# STMP3770 register map
Vendor: Freescale Semiconductor (NXP); Series: STMP37xx; File version: 1.0
CPU: other r0p0, little endian, no MPU, no FPU, 2 interrupt priority bits
Registers are 32-bit, read-write, reset 0x0 unless marked. A register's access mark holds for its fields unless they carry their own. Offsets are from the block's base; [hi:lo] are bit positions; {n}, {i} and the like mark numbered series.

## LCDIF — STMP3770 LCDIF (eLCDIF) 显示控制器，支持 MPU/8080 并行接口、VSYNC 模式与 DOTCLK 模式，集成 DMA 帧缓冲、RGB-to-YCbCr 4:2:2 CSC 转换、DVI 输出及引脚共享仲裁。基地址 0x80030000。
Base 0x80030000
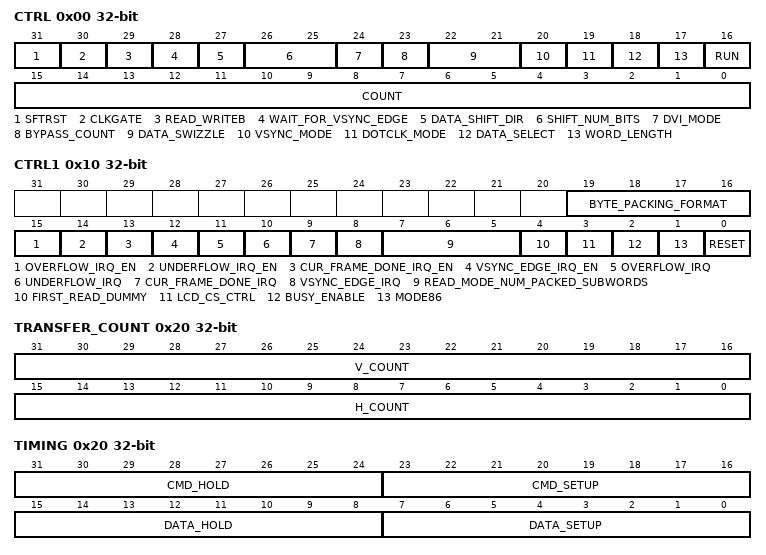
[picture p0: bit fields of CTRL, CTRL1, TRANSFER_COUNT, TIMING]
0x00 CTRL — LCDIF 通用控制寄存器，控制数据传输启动、数据格式、接口模式、字节序、移位及复位等全局行为。
  [31] SFTRST — 软复位，写 1 对 LCDIF 模块进行软件复位。
  [30] CLKGATE — 时钟门控，1 时关闭 LCDIF 内部时钟以节省功耗。
  [29] READ_WRITEB — 读写方向控制，0=写（发送），1=读（接收）。
  [28] WAIT_FOR_VSYNC_EDGE — 等待 VSYNC 边沿后再启动帧传输，用于帧同步对齐。
  [27] DATA_SHIFT_DIR — 数据移位方向，0=左移，1=右移。
    0=TXDATA_SHIFT_LEFT; 1=TXDATA_SHIFT_RIGHT
  [26:25] SHIFT_NUM_BITS — 数据移位的位数（0-3），指定像素数据在输出前左/右移的位数。
  [24] DVI_MODE — DVI 输出模式使能，1 时启用 DVI/数字视频接口输出。
  [23] BYPASS_COUNT — 旁路内部行列计数器，1 时由外部逻辑或 DMA 直接控制传输终止。
  [22:21] DATA_SWIZZLE — 输入数据字节序调整（Swizzle），控制 32 位字内各字节的排列顺序。
  [20] VSYNC_MODE — VSYNC 接口模式使能，1 表示使用 VSYNC 同步模式。
  [19] DOTCLK_MODE — DOTCLK 接口模式使能，1 表示使用同步 DOTCLK 时序驱动 RGB 屏。
  [18] DATA_SELECT — MPU/8080 接口命令/数据选择，0=命令模式，1=数据模式。
    0=CMD_MODE; 1=DATA_MODE
  [17] WORD_LENGTH — 像素字长选择，0=16 位，1=24 位。
    0=NO_SWAP; 1=BIG_ENDIAN_SWAP
  [16] RUN — 启动 LCDIF 数据传输，写 1 使能传输引擎运行。
    0=_16_BIT; 1=_8_BIT
  [15:0] COUNT — LCD 数据格式选择，编码像素数据输出位宽（0=16 位，1=8 位，2=18 位，3=24 位）。
    0=_16_BIT; 1=_8_BIT; 2=_18_BIT; 3=_24_BIT
0x10 CTRL1 — LCDIF 通用控制寄存器 1，包含 LCD 复位、接口子模式、中断状态/使能及字节打包格式。
  [19:16] BYTE_PACKING_FORMAT — 字节打包格式，32 位字内各字节通道的有效/无效掩码，用于非 32 位对齐像素格式。
  [15] OVERFLOW_IRQ_EN — 溢出中断使能，1 时允许 OVERFLOW_IRQ 产生中断。
  [14] UNDERFLOW_IRQ_EN — 下溢中断使能，1 时允许 UNDERFLOW_IRQ 产生中断。
  [13] CUR_FRAME_DONE_IRQ_EN — 当前帧完成中断使能，1 时允许 CUR_FRAME_DONE_IRQ 产生中断。
  [12] VSYNC_EDGE_IRQ_EN — VSYNC 边沿中断使能，1 时允许 VSYNC_EDGE_IRQ 产生中断。
  [11] OVERFLOW_IRQ — 溢出中断状态，1 表示 RXFIFO/TXFIFO 溢出中断请求。
    0=NO_REQUEST; 1=REQUEST
  [10] UNDERFLOW_IRQ — 下溢中断状态，1 表示 TXFIFO 下溢中断请求。
    0=NO_REQUEST; 1=REQUEST
  [9] CUR_FRAME_DONE_IRQ — 当前帧完成中断状态，1 表示当前帧传输完成中断请求。
    0=NO_REQUEST; 1=REQUEST
  [8] VSYNC_EDGE_IRQ — VSYNC 边沿中断状态，1 表示检测到 VSYNC 边沿中断请求。
    0=NO_REQUEST; 1=REQUEST
  [7:5] READ_MODE_NUM_PACKED_SUBWORDS — 读模式下每字内打包的子字数量，决定一次 32 位读操作中包含的有效像素子字数。
  [4] FIRST_READ_DUMMY — 首次读虚拟周期请求，1 时在读序列开头插入一个虚拟读周期。
    0=NO_REQUEST; 1=REQUEST
  [3] LCD_CS_CTRL — LCD 片选信号控制，直接控制 CS 引脚输出电平。
  [2] BUSY_ENABLE — BUSY 信号检测使能，1 时 LCDIF 在 MPU 读/写期间检测外部 BUSY 信号。
    0=BUSY_DISABLED; 1=BUSY_ENABLED
  [1] MODE86 — MPU 接口子模式选择，0=8080 模式，1=6800 模式。
    0=_8080_MODE; 1=_6800_MODE
  [0] RESET — LCD 面板硬件复位信号控制，0=低电平复位，1=高电平释放。
    0=LCDRESET_LOW; 1=LCDRESET_HIGH
0x20 TRANSFER_COUNT (alternate view of TIMING) — LCDIF 有效数据传输计数寄存器，定义一帧内水平与垂直方向的像素数量。
  [31:16] V_COUNT — 垂直方向有效像素计数（行数）。
  [15:0] H_COUNT — 水平方向有效像素计数（每行像素数）。
0x20 TIMING — LCD 接口时序寄存器，配置 MPU/8080 并行接口的命令与数据建立/保持周期。注：该物理地址在 System 模式下为 TRANSFER_COUNT。
  [31:24] CMD_HOLD — 命令写操作的保持周期数（WR 无效后 CMD 保持有效的时钟数）。
  [23:16] CMD_SETUP — 命令写操作的建立周期数（CMD 有效到 WR 有效之间的等待时钟数）。
  [15:8] DATA_HOLD — 数据写操作的保持周期数（WR 无效后 DATA 保持有效的时钟数）。
  [7:0] DATA_SETUP — 数据写操作的建立周期数（DATA 有效到 WR 有效之间的等待时钟数）。
0x30 CUR_BUF (alternate view of VDCTRL1) — LCD 接口当前帧缓冲地址寄存器，存储 DMA 当前正在传输的帧数据物理地址。
  [31:0] ADDR — 当前帧缓冲在系统内存中的 32 位物理地址。
0x30 VDCTRL1 — LCDIF VSYNC/DOTCLK 模式控制寄存器 1，定义 VSYNC 周期（帧总周期）。注：该物理地址在 System 模式下为 CUR_BUF。
  [31:0] VSYNC_PERIOD — VSYNC 周期值，表示一帧的总时钟周期数（含有效与消隐区）。
0x40 NEXT_BUF (alternate view of VDCTRL2) — LCD 接口下一帧缓冲地址寄存器，存储 DMA 下一帧待传输的帧数据物理地址。
  [31:0] ADDR — 下一帧缓冲在系统内存中的 32 位物理地址，硬件在当前帧完成后自动切换。
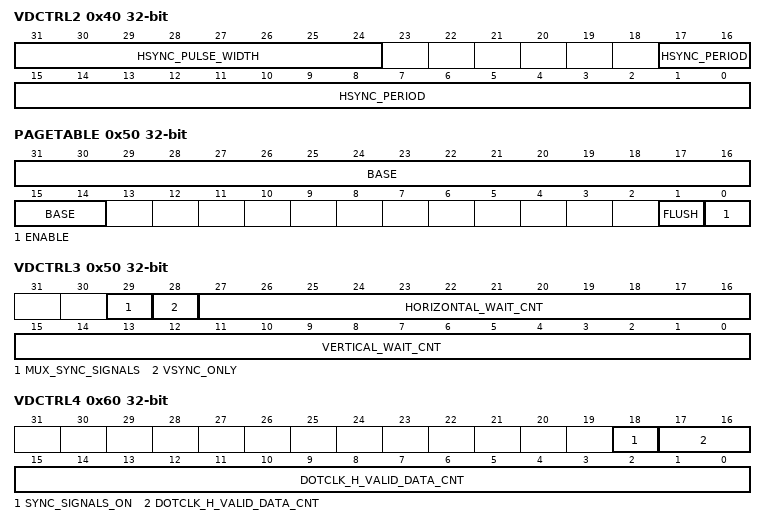
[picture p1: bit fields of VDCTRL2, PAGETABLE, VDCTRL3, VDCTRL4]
0x40 VDCTRL2 — LCDIF VSYNC/DOTCLK 模式控制寄存器 2，定义 HSYNC 周期与脉冲宽度。注：该物理地址在 System 模式下为 NEXT_BUF。
  [31:24] HSYNC_PULSE_WIDTH — HSYNC 脉冲宽度，表示水平同步脉冲持续的有效时钟周期数。
  [17:0] HSYNC_PERIOD — HSYNC 周期值，表示一行的总时钟周期数（含有效与消隐区）。
0x50 PAGETABLE (alternate view of VDCTRL3) — LCDIF 页表寄存器，使能 DMA 页表寻址并配置页表基地址。
  [31:14] BASE — 页表基地址的高 18 位（以 16KB 对齐），指向内存中的页表起始位置。
  [1] FLUSH — 页表刷新，写 1 强制刷新内部页表缓存。
  [0] ENABLE — 页表机制使能，1 时 DMA 通过页表进行分散/聚集式地址转换。
0x50 VDCTRL3 — LCDIF VSYNC/DOTCLK 模式控制寄存器 3，配置行列等待计数及同步信号复用。注：该物理地址在 System 模式下为 PAGETABLE。
  [29] MUX_SYNC_SIGNALS — 同步信号复用使能，1 时将 VSYNC/HSYNC/ENABLE 信号复用输出。
  [28] VSYNC_ONLY — 仅 VSYNC 模式，1 时关闭 DOTCLK 输出，仅使用 VSYNC 同步。
  [27:16] HORIZONTAL_WAIT_CNT — 水平等待计数，表示 HSYNC 有效后到首像素有效数据前的时钟等待周期数。
  [15:0] VERTICAL_WAIT_CNT — 垂直等待计数，表示 VSYNC 有效后到首行有效数据前的行等待周期数。
0x60 VDCTRL4 — LCDIF VSYNC/DOTCLK 模式控制寄存器 4，配置水平有效数据计数及同步信号强制输出。
  [18] SYNC_SIGNALS_ON — 强制同步信号输出使能，1 时持续输出 HSYNC/VSYNC/ENABLE 波形。
  [17:0] DOTCLK_H_VALID_DATA_CNT — DOTCLK 模式下每行有效数据像素计数。
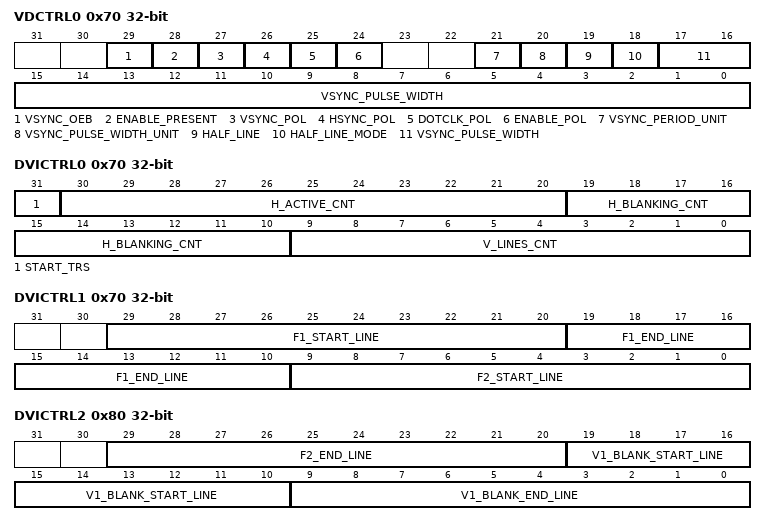
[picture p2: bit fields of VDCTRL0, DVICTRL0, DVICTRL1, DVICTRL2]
0x70 VDCTRL0 — LCDIF VSYNC/DOTCLK 模式控制寄存器 0，配置 VSYNC 脉冲宽度、极性、半行模式及同步信号属性。
  [29] VSYNC_OEB — VSYNC 引脚方向控制，0=输出（内部产生 VSYNC），1=输入（外部接收 VSYNC）。
    0=VSYNC_OUTPUT; 1=VSYNC_INPUT
  [28] ENABLE_PRESENT — 数据使能信号（ENABLE/DE）存在标志，1 表示接口使用 DE 信号。
  [27] VSYNC_POL — VSYNC 垂直同步极性，0=低电平有效，1=高电平有效。
  [26] HSYNC_POL — HSYNC 水平同步极性，0=低电平有效，1=高电平有效。
  [25] DOTCLK_POL — DOTCLK 像素时钟极性，0=上升沿采样，1=下降沿采样。
  [24] ENABLE_POL — 数据使能信号（ENABLE/DE）极性，0=低电平有效，1=高电平有效。
  [21] VSYNC_PERIOD_UNIT — VSYNC 周期单位，0=以像素时钟为单位，1=以行为单位。
  [20] VSYNC_PULSE_WIDTH_UNIT — VSYNC 脉冲宽度单位，0=以像素时钟为单位，1=以行为单位。
  [19] HALF_LINE — 半行指示，当前处于半行扫描状态标志（只读）。
  [18] HALF_LINE_MODE — 半行模式使能，1 时每帧按半行粒度进行扫描时序控制。
  [17:0] VSYNC_PULSE_WIDTH — VSYNC 脉冲宽度，表示垂直同步脉冲持续的有效时钟周期数。
0x70 DVICTRL0 (alternate view of VDCTRL0) — 数字视频接口控制寄存器 0，配置 DVI 输出时视频帧的行数、水平消隐与有效像素。注：该物理地址在 VSYNC/DOTCLK 模式下为 VDCTRL0。
  [31] START_TRS — DVI 传输启动，写 1 开始 DVI 数据流输出。
  [30:20] H_ACTIVE_CNT — 水平有效像素计数（每行中有效像素数）。
  [19:10] H_BLANKING_CNT — 水平消隐期像素计数（每行中无效像素时钟数）。
  [9:0] V_LINES_CNT — 每帧有效视频行数（垂直方向总行数）。
0x70 DVICTRL1 (alternate view of VDCTRL0) — 数字视频接口控制寄存器 1，配置隔行扫描时场 1 与场 2 的起止行位置。注：该物理地址在 VSYNC/DOTCLK 模式下为 VDCTRL0，与 DVICTRL0 共享地址。
  [29:20] F1_START_LINE — 场 1（F1）起始行号，定义隔行扫描第一场的第一有效行。
  [19:10] F1_END_LINE — 场 1（F1）结束行号，定义隔行扫描第一场的最后一有效行。
  [9:0] F2_START_LINE — 场 2（F2）起始行号，定义隔行扫描第二场的第一有效行。
0x80 DVICTRL2 — 数字视频接口控制寄存器 2，配置场 1 垂直消隐及场 2 结束行位置。
  [29:20] F2_END_LINE — 场 2（F2）结束行号，定义隔行扫描第二场的最后一有效行。
  [19:10] V1_BLANK_START_LINE — 场 1 垂直消隐开始行号，定义第一场有效视频结束、消隐开始的行。
  [9:0] V1_BLANK_END_LINE — 场 1 垂直消隐结束行号，定义第一场消隐期结束、有效视频开始的行。
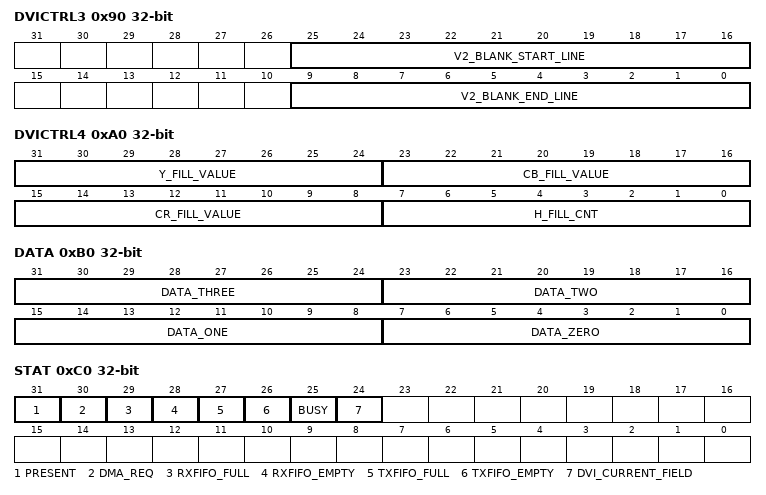
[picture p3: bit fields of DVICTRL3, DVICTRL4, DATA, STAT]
0x90 DVICTRL3 — 数字视频接口控制寄存器 3，配置场 2 垂直消隐起止行位置。
  [25:16] V2_BLANK_START_LINE — 场 2 垂直消隐开始行号，定义第二场有效视频结束、消隐开始的行。
  [9:0] V2_BLANK_END_LINE — 场 2 垂直消隐结束行号，定义第二场消隐期结束、有效视频开始的行。
0xA0 DVICTRL4 — 数字视频接口控制寄存器 4，配置 DVI 水平填充计数及 YCbCr 填充值。
  [31:24] Y_FILL_VALUE — Y 亮度填充值，消隐期输出的 Y 分量默认值。
  [23:16] CB_FILL_VALUE — Cb 色度填充值，消隐期输出的 Cb 分量默认值。
  [15:8] CR_FILL_VALUE — Cr 色度填充值，消隐期输出的 Cr 分量默认值。
  [7:0] H_FILL_CNT — 水平填充像素计数，定义每行消隐期插入的填充像素数。
0xB0 DATA — LCD 接口数据寄存器，用于 PIO 方式直接写入 4 字节像素数据到 TXFIFO。
  [31:24] DATA_THREE — 字节 3 数据，32 位字中最高有效字节对应的像素数据。
  [23:16] DATA_TWO — 字节 2 数据，32 位字中次高字节对应的像素数据。
  [15:8] DATA_ONE — 字节 1 数据，32 位字中次低字节对应的像素数据。
  [7:0] DATA_ZERO — 字节 0 数据，32 位字中最低有效字节对应的像素数据。
0xC0 BM_ERROR_STAT ro (alternate view of STAT) — 总线主设备错误状态寄存器，记录 DMA 传输发生总线错误时的出错地址。注：该物理地址在其他模式下作为 STAT（状态寄存器）使用。
  [31:0] ADDR — DMA 总线错误发生时的 32 位出错内存地址。
0xC0 STAT — LCD 接口状态寄存器，反映当前运行状态、FIFO 状态及 DMA 请求标志。注：该物理地址在 System 模式下为 BM_ERROR_STAT（总线错误状态寄存器）。
  [31] PRESENT — 模块存在标志，1 表示 LCDIF 硬件模块已集成并可用。
  [30] DMA_REQ — DMA 请求标志，1 表示 LCDIF 正在向 DMA 控制器请求数据传输。
  [29] RXFIFO_FULL — 接收 FIFO 满标志，1 表示 RXFIFO 已满。
  [28] RXFIFO_EMPTY — 接收 FIFO 空标志，1 表示 RXFIFO 已空。
  [27] TXFIFO_FULL — 发送 FIFO 满标志，1 表示 TXFIFO 已满。
  [26] TXFIFO_EMPTY — 发送 FIFO 空标志，1 表示 TXFIFO 已空。
  [25] BUSY — 忙标志，1 表示 LCDIF 正在执行数据传输或时序生成。
  [24] DVI_CURRENT_FIELD — DVI 当前场指示，0=场 1，1=场 2（隔行输出时）。
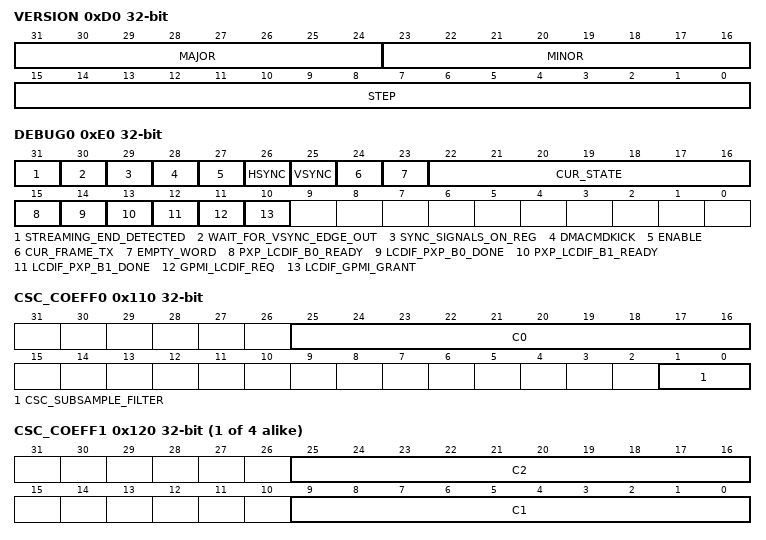
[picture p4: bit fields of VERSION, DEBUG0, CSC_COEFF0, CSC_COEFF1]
0xD0 VERSION ro — LCD 接口版本寄存器，读取硬件版本号（主/次/步进）。
  [31:24] MAJOR — 主版本号（MAJOR），标识当前硬件的主要版本。
  [23:16] MINOR — 次版本号（MINOR），标识当前硬件的次要版本。
  [15:0] STEP — 步进版本号（STEP），标识当前硬件的修订步进。
0xE0 DEBUG0 ro — LCD 接口调试寄存器 0，提供内部状态机、握手信号及同步信号的实时快照。
  [31] STREAMING_END_DETECTED — 流结束检测标志，1 表示 LCDIF 检测到数据流传输结束。
  [30] WAIT_FOR_VSYNC_EDGE_OUT — WAIT_FOR_VSYNC_EDGE 输出的实时状态，反映 CTRL 中该位的内部生效状态。
  [29] SYNC_SIGNALS_ON_REG — 同步信号强制输出寄存器位的实时状态，反映 VDCTRL4.SYNC_SIGNALS_ON 的生效状态。
  [28] DMACMDKICK — DMA 命令触发（Kick）信号，1 表示 DMA 命令已被触发执行。
  [27] ENABLE — 内部 ENABLE/DE 数据使能信号实时状态。
  [26] HSYNC — 内部 HSYNC 信号实时状态。
  [25] VSYNC — 内部 VSYNC 信号实时状态。
  [24] CUR_FRAME_TX — 当前帧传输中标志，1 表示 LCDIF 正在传输当前帧数据。
  [23] EMPTY_WORD — 空字标志，1 表示当前 TXFIFO 输出为空字（填充数据）。
  [22:16] CUR_STATE — 当前状态机状态码，反映 LCDIF 内部控制状态机的当前状态编号。
  [15] PXP_LCDIF_B0_READY — PXP 到 LCDIF 的 Buffer 0 就绪信号，1 表示 PXP 已准备好 Buffer 0 数据供 LCDIF 读取。
  [14] LCDIF_PXP_B0_DONE — LCDIF 到 PXP 的 Buffer 0 完成信号，1 表示 LCDIF 已完成 Buffer 0 的像素处理。
  [13] PXP_LCDIF_B1_READY — PXP 到 LCDIF 的 Buffer 1 就绪信号，1 表示 PXP 已准备好 Buffer 1 数据供 LCDIF 读取。
  [12] LCDIF_PXP_B1_DONE — LCDIF 到 PXP 的 Buffer 1 完成信号，1 表示 LCDIF 已完成 Buffer 1 的像素处理。
  [11] GPMI_LCDIF_REQ — GPMI 向 LCDIF 发出的引脚共享请求信号。
  [10] LCDIF_GPMI_GRANT — GPMI 对 LCDIF 的引脚共享授权信号，1 表示 GPMI 已授权 LCDIF 使用共享引脚。
0x110 CSC_COEFF0 — RGB 到 YCbCr 4:2:2 色彩空间转换系数寄存器 0，配置色度子采样滤波器及 CSC 矩阵系数 C0。
  [25:16] C0 — CSC 转换矩阵系数 C0（10 位有符号定点数），用于 RGB 到 YCbCr 的线性变换。
  [1:0] CSC_SUBSAMPLE_FILTER — 色度子采样滤波器模式选择，0=采样保持，2=间插式，3=共位式。
    0=SAMPLE_AND_HOLD; 1=RSRVD; 2=INTERSTITIAL; 3=COSITED
{0x110+0x10*i} CSC_COEFF{i} (i=1..4) — RGB 到 YCbCr 4:2:2 色彩空间转换系数寄存器 {i}，配置 CSC 矩阵系数 C{2i-1} 与 C{2i}。
  [25:16] C{2i} — CSC 转换矩阵系数 C{2i}（10 位有符号定点数）。
  [9:0] C{2i-1} — CSC 转换矩阵系数 C{2i-1}（10 位有符号定点数）。
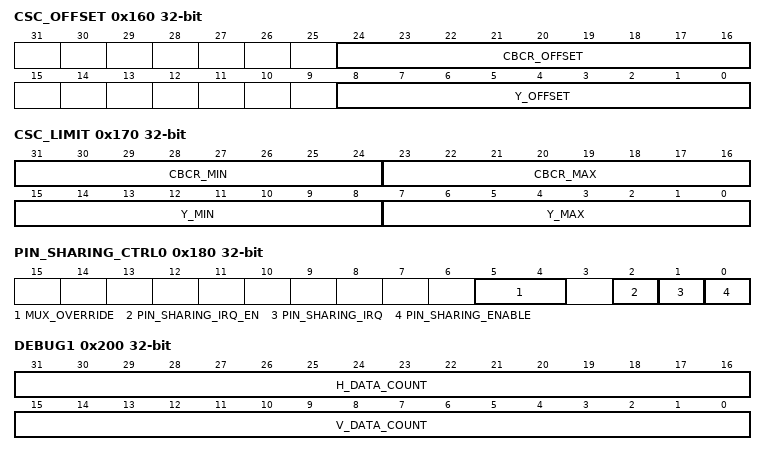
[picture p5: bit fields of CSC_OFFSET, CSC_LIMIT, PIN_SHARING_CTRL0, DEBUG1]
0x160 CSC_OFFSET — RGB 到 YCbCr 4:2:2 色彩空间转换偏移寄存器，配置 Y 与 CbCr 的亮度/色度偏移量。
  [24:16] CBCR_OFFSET — Cb/Cr 色度分量偏移量（9 位有符号数），用于 CSC 转换后的色度平移。
  [8:0] Y_OFFSET — Y 亮度分量偏移量（9 位有符号数），用于 CSC 转换后的亮度平移。
0x170 CSC_LIMIT — RGB 到 YCbCr 4:2:2 色彩空间转换限幅寄存器，配置 Y 与 CbCr 的输出上下限。
  [31:24] CBCR_MIN — Cb/Cr 色度分量输出最小值（下限限幅值）。
  [23:16] CBCR_MAX — Cb/Cr 色度分量输出最大值（上限限幅值）。
  [15:8] Y_MIN — Y 亮度分量输出最小值（下限限幅值）。
  [7:0] Y_MAX — Y 亮度分量输出最大值（上限限幅值）。
0x180 PIN_SHARING_CTRL0 — 引脚共享控制寄存器 0，使能 LCDIF 与 GPMI 的引脚共享仲裁，并配置中断与复用覆盖。
  [5:4] MUX_OVERRIDE — 引脚复用覆盖选择，0=无覆盖，2=强制 LCDIF 使用，3=强制 GPMI 使用。
    0=NO_OVERRIDE; 1=RSRVD; 2=LCDIF_SEL; 3=GPMI_SEL
  [2] PIN_SHARING_IRQ_EN — 引脚共享中断使能，1 时允许 PIN_SHARING_IRQ 产生中断。
  [1] PIN_SHARING_IRQ — 引脚共享中断状态，1 表示引脚共享仲裁事件产生中断请求。
    0=NO_REQUEST; 1=REQUEST
  [0] PIN_SHARING_ENABLE — 引脚共享机制使能，1 时允许 LCDIF 与 GPMI 通过仲裁共享外部数据总线引脚。
0x190 PIN_SHARING_CTRL1 — 引脚共享控制寄存器 1，配置引脚共享仲裁阈值 1（GPMI 优先阈值或时间窗口）。
  [31:0] THRESHOLD1 — 引脚共享仲裁阈值 1，用于控制 LCDIF 与 GPMI 之间的总线占用时间分配。
0x1A0 PIN_SHARING_CTRL2 — 引脚共享控制寄存器 2，配置引脚共享仲裁阈值 2（LCDIF 优先阈值或时间窗口）。
  [31:0] THRESHOLD2 — 引脚共享仲裁阈值 2，用于控制 LCDIF 与 GPMI 之间的总线占用时间分配。
0x200 DEBUG1 ro — LCD 接口调试寄存器 1，提供内部垂直与水平像素计数器的实时值。
  [31:16] H_DATA_COUNT — 水平数据计数器，当前行已传输的像素数（有效数据像素计数）。
  [15:0] V_DATA_COUNT — 垂直数据计数器，当前帧已传输的行数（有效数据行计数）。
